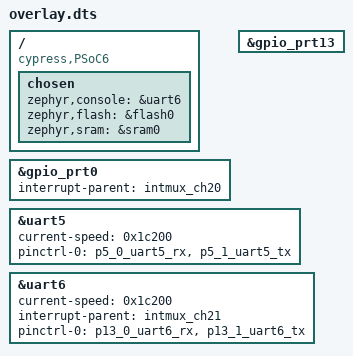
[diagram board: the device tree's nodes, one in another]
/ {
	compatible = "cypress,PSoC6", "cypress,cy8ckit_062_wifi_bt_m0";
	chosen {
		zephyr,console = &uart6;
		zephyr,flash = &flash0;
		zephyr,sram = &sram0;
	};
};
&gpio_prt0{
	status = "okay";
	interrupt-parent = < &intmux_ch20 >;
};
&gpio_prt13{
	status = "okay";
};
&uart5{
	status = "okay";
	current-speed = < 0x1c200 >;
	pinctrl-0 = < &p5_0_uart5_rx &p5_1_uart5_tx >;
};
&uart6{
	status = "okay";
	current-speed = < 0x1c200 >;
	interrupt-parent = < &intmux_ch21 >;
	pinctrl-0 = < &p13_0_uart6_rx &p13_1_uart6_tx >;
};
